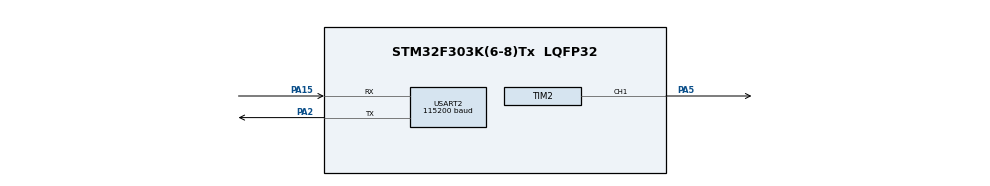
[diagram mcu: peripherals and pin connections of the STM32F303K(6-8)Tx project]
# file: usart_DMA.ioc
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Dma.Request0=USART2_RX
Dma.Request1=USART2_TX
Dma.USART2_RX.0.Direction=DMA_PERIPH_TO_MEMORY
Dma.USART2_RX.0.Instance=DMA1_Channel6
Dma.USART2_RX.0.MemDataAlignment=DMA_MDATAALIGN_BYTE
Dma.USART2_RX.0.MemInc=DMA_MINC_ENABLE
Dma.USART2_RX.0.Mode=DMA_CIRCULAR
Dma.USART2_RX.0.PeriphDataAlignment=DMA_PDATAALIGN_BYTE
Dma.USART2_RX.0.PeriphInc=DMA_PINC_DISABLE
Dma.USART2_RX.0.Priority=DMA_PRIORITY_MEDIUM
Dma.USART2_TX.1.Direction=DMA_MEMORY_TO_PERIPH
Dma.USART2_TX.1.Instance=DMA1_Channel7
Dma.USART2_TX.1.MemDataAlignment=DMA_MDATAALIGN_BYTE
Dma.USART2_TX.1.MemInc=DMA_MINC_ENABLE
Dma.USART2_TX.1.Mode=DMA_NORMAL
Dma.USART2_TX.1.PeriphDataAlignment=DMA_PDATAALIGN_BYTE
Dma.USART2_TX.1.PeriphInc=DMA_PINC_DISABLE
Dma.USART2_TX.1.Priority=DMA_PRIORITY_MEDIUM
Mcu.Family=STM32F3
Mcu.Name=STM32F303K(6-8)Tx
Mcu.Package=LQFP32
NVIC.DMA1_Channel6_IRQn=true\:0\:0\:false\:false\:true\:false\:true
NVIC.DMA1_Channel7_IRQn=true\:0\:0\:false\:false\:true\:false\:true
NVIC.PriorityGroup=NVIC_PRIORITYGROUP_4
NVIC.TIM3_IRQn=true\:0\:0\:false\:false\:true\:true\:true
PA15.Mode=Asynchronous
PA15.Signal=USART2_RX
PA2.Mode=Asynchronous
PA2.Signal=USART2_TX
PA5.Signal=S_TIM2_CH1_ETR
ProjectManager.HeapSize=0x200
ProjectManager.StackSize=0x400
ProjectManager.TargetToolchain=STM32CubeIDE
RCC.AHBFreq_Value=8000000
RCC.APB1Freq_Value=8000000
RCC.APB2Freq_Value=8000000
RCC.CortexFreq_Value=8000000
RCC.HSE_VALUE=8000000
RCC.HSI_VALUE=8000000
RCC.SYSCLKFreq_VALUE=8000000
SH.S_TIM2_CH1_ETR.0=TIM2_CH1,PWM Generation1 CH1
TIM2.Channel-PWM\ Generation1\ CH1=TIM_CHANNEL_1
TIM2.Period=99
TIM2.Prescaler=799
TIM3.Channel-Output\ Compare1\ No\ Output=TIM_CHANNEL_1
TIM3.OCMode_1=TIM_OCMODE_ACTIVE
TIM3.Period=9
TIM3.Prescaler=7999
USART2.BaudRate=115200
USART2.VirtualMode-Asynchronous=VM_ASYNC
VP_TIM2_VS_ClockSourceINT.Mode=Internal
VP_TIM3_VS_ClockSourceINT.Mode=Internal
VP_TIM3_VS_no_output1.Mode=Output Compare1 No Output
board=custom

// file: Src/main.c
/* USER CODE BEGIN Header */
/**
  ******************************************************************************
  * @file           : main.c
  * @brief          : Main program body
  ******************************************************************************
  * @attention
  *
  * <h2><center>&copy; Copyright (c) 2019 STMicroelectronics.
  * All rights reserved.</center></h2>
  *
  * This software component is licensed by ST under BSD 3-Clause license,
  * the "License"; You may not use this file except in compliance with the
  * License. You may obtain a copy of the License at:
  *                        opensource.org/licenses/BSD-3-Clause
  *
  ******************************************************************************
  */
/* USER CODE END Header */

#include "main.h"
#include "dma.h"
#include "tim.h"
#include "usart.h"
#include "gpio.h"
#include <stdio.h>
#include <string.h>

void SystemClock_Config(void);

/* USER CODE BEGIN 0 */
void proccesDmaData(const uint8_t* data, uint16_t len);

/* Space for your global variables. */

	int test= 0;
	uint8_t test_message[] = "Print this message if works";

	// type your global variables here:
	int start = 0;
	int count = 0;
	int capL = 0;
	int lowL = 0;

/* USER CODE END 0 */

int main(void)
{
  /* USER CODE BEGIN 1 */
  uint8_t tx_data[1000];
  uint8_t tx_data1[] = "Buffer capacity: ";
  uint8_t tx_data2[] = " bytes, occupied memory: ";

  uint8_t tx_data3[] = " bytes, load [in %]: ";

  uint8_t tx_data4[] = "%\r\n";

  char buffer_size_string[4];
  char used_memory_string[10];
  char load_string[3];
  int buffer_size_int = DMA_USART2_BUFFER_SIZE;
  sprintf(buffer_size_string, "%d", buffer_size_int);

  	  //type your code here:
  USART2_RegisterCallback(proccesDmaData);

  /* USER CODE END 1 */

  /* MCU Configuration--------------------------------------------------------*/

  /* Reset of all peripherals, Initializes the Flash interface and the Systick. */
  HAL_Init();

  /* Configure the system clock */
  SystemClock_Config();

  /* Initialize all configured peripherals */
  MX_GPIO_Init();
  MX_DMA_Init();
  MX_USART2_UART_Init();
  MX_TIM2_Init();
  MX_TIM3_Init();

  /* Infinite loop */
  while (1)
  {

    /* USER CODE BEGIN 3 */
	  /* Periodic transmission of information about DMA Rx buffer state.
	   * Transmission frequency - 5Hz.
	   * Message format - "Buffer capacity: %d bytes, occupied memory: %d bytes, load [in %]: %f%"
	   * Example message (what I wish to see in terminal) - Buffer capacity: 1000 bytes, occupied memory: 231 bytes, load [in %]: 23.1%
	   */

  	  	  	  //type your code here:
		#if POLLING
	  	//Polling for new data, no interrupts
	  		USART2_CheckDmaReception();
	  		LL_mDelay(10);
		#else
	  		USART2_PutBuffer(tx_data, sizeof(tx_data));
	  		LL_mDelay(1000);
		#endif

		//memset(tx_data,0,1000);

		sprintf(used_memory_string, "%d", occupied_memory);
		//itoa(occupied_memory, used_memory_string, 10);
		gcvt(load, 4, load_string);

		//strcat(tx_data, tx_data1);

		USART2_PutBuffer(tx_data1, sizeof(tx_data1));
		USART2_PutBuffer(buffer_size_string, sizeof(buffer_size_string));
		USART2_PutBuffer(tx_data2, sizeof(tx_data2));
		USART2_PutBuffer(used_memory_string, sizeof(used_memory_string));
		USART2_PutBuffer(tx_data3, sizeof(tx_data3));
		USART2_PutBuffer(load_string, sizeof(load_string));
		USART2_PutBuffer(tx_data4, sizeof(tx_data4));

		/*strcat(tx_data, buffer_size_string);
		strcat(tx_data, tx_data2);
		strcat(tx_data, used_memory_string);
		strcat(tx_data, tx_data3);
		strcat(tx_data, load_string);
		strcat(tx_data, tx_data4);*/

		if(test)
		{
			USART2_PutBuffer(test_message, sizeof(test_message));
		}

		 //USART2_PutBuffer(tx_data, sizeof(tx_data));

	  	LL_mDelay(200);

  }
  /* USER CODE END 3 */
}

void SystemClock_Config(void)
{
  LL_FLASH_SetLatency(LL_FLASH_LATENCY_0);

  if(LL_FLASH_GetLatency() != LL_FLASH_LATENCY_0)
  {
  Error_Handler();
  }
  LL_RCC_HSI_Enable();

   /* Wait till HSI is ready */
  while(LL_RCC_HSI_IsReady() != 1)
  {

  }
  LL_RCC_HSI_SetCalibTrimming(16);
  LL_RCC_SetAHBPrescaler(LL_RCC_SYSCLK_DIV_1);
  LL_RCC_SetAPB1Prescaler(LL_RCC_APB1_DIV_1);
  LL_RCC_SetAPB2Prescaler(LL_RCC_APB1_DIV_1);
  LL_RCC_SetSysClkSource(LL_RCC_SYS_CLKSOURCE_HSI);

   /* Wait till System clock is ready */
  while(LL_RCC_GetSysClkSource() != LL_RCC_SYS_CLKSOURCE_STATUS_HSI)
  {

  }
  LL_Init1msTick(8000000);
  LL_SYSTICK_SetClkSource(LL_SYSTICK_CLKSOURCE_HCLK);
  LL_SetSystemCoreClock(8000000);
}

/* USER CODE BEGIN 4 */
void proccesDmaData(const uint8_t* data, uint16_t len)
{
	/* Process received data */

		// type your algorithm here:

	for(uint8_t i = 0; i < len; i++)
	{
		if(*(data+i) == '#')
		{
			start = 1;
		}
		else if(*(data+i) == '$')
		{
			start = 0;
			count = 0;
			lowL = 0;
		    capL = 0;
		}

		if(start == 1)
		{
			count++;
			if(count >= 34)
			{
				start = 0;
				count = 0;
				lowL = 0;
				capL = 0;
			}
			else
			{
				if(*(data+i) > 96 && *(data+i) < 123)
				{
					lowL++;
				}
				if(*(data+i) > 64 && *(data+i) < 91)
				{
					capL++;
				}
			}

		}

	}
}

/* USER CODE END 4 */

void Error_Handler(void)
{
}

/************************ (C) COPYRIGHT STMicroelectronics *****END OF FILE****/
